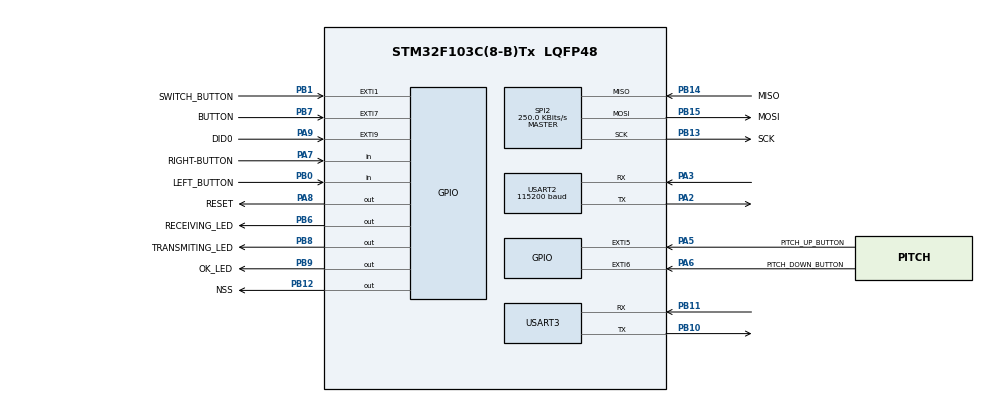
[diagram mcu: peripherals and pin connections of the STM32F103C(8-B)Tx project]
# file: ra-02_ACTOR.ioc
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Dma.Request0=USART2_TX
Dma.Request1=USART3_TX
Dma.Request2=USART3_RX
Dma.USART2_TX.0.Direction=DMA_MEMORY_TO_PERIPH
Dma.USART2_TX.0.Instance=DMA1_Channel7
Dma.USART2_TX.0.MemDataAlignment=DMA_MDATAALIGN_BYTE
Dma.USART2_TX.0.MemInc=DMA_MINC_ENABLE
Dma.USART2_TX.0.Mode=DMA_NORMAL
Dma.USART2_TX.0.PeriphDataAlignment=DMA_PDATAALIGN_BYTE
Dma.USART2_TX.0.PeriphInc=DMA_PINC_DISABLE
Dma.USART2_TX.0.Priority=DMA_PRIORITY_VERY_HIGH
Dma.USART3_RX.2.Direction=DMA_PERIPH_TO_MEMORY
Dma.USART3_RX.2.Instance=DMA1_Channel3
Dma.USART3_RX.2.MemDataAlignment=DMA_MDATAALIGN_BYTE
Dma.USART3_RX.2.MemInc=DMA_MINC_ENABLE
Dma.USART3_RX.2.Mode=DMA_NORMAL
Dma.USART3_RX.2.PeriphDataAlignment=DMA_PDATAALIGN_BYTE
Dma.USART3_RX.2.PeriphInc=DMA_PINC_DISABLE
Dma.USART3_RX.2.Priority=DMA_PRIORITY_LOW
Dma.USART3_TX.1.Direction=DMA_MEMORY_TO_PERIPH
Dma.USART3_TX.1.Instance=DMA1_Channel2
Dma.USART3_TX.1.MemDataAlignment=DMA_MDATAALIGN_BYTE
Dma.USART3_TX.1.MemInc=DMA_MINC_ENABLE
Dma.USART3_TX.1.Mode=DMA_NORMAL
Dma.USART3_TX.1.PeriphDataAlignment=DMA_PDATAALIGN_BYTE
Dma.USART3_TX.1.PeriphInc=DMA_PINC_DISABLE
Dma.USART3_TX.1.Priority=DMA_PRIORITY_LOW
FREERTOS.Tasks01=defaultTask,24,128,StartDefaultTask,Default,NULL,Dynamic,NULL,NULL
FREERTOS.configENABLE_FPU=1
FREERTOS.configTOTAL_HEAP_SIZE=1024
FREERTOS.configUSE_NEWLIB_REENTRANT=1
Mcu.Family=STM32F1
Mcu.Name=STM32F103C(8-B)Tx
Mcu.Package=LQFP48
NVIC.DMA1_Channel2_IRQn=true\:5\:0\:false\:false\:true\:true\:false\:true\:true
NVIC.DMA1_Channel3_IRQn=true\:5\:0\:false\:false\:true\:true\:false\:true\:true
NVIC.DMA1_Channel7_IRQn=true\:5\:0\:false\:false\:true\:true\:false\:true\:true
NVIC.EXTI1_IRQn=true\:5\:0\:false\:false\:true\:true\:true\:true\:true
NVIC.EXTI9_5_IRQn=true\:5\:0\:false\:false\:true\:true\:true\:true\:true
NVIC.PriorityGroup=NVIC_PRIORITYGROUP_4
NVIC.TIM3_IRQn=true\:15\:0\:false\:false\:true\:false\:false\:true\:true
NVIC.TimeBase=TIM3_IRQn
NVIC.TimeBaseIP=TIM3
NVIC.USART2_IRQn=true\:5\:0\:false\:false\:true\:true\:true\:true\:true
NVIC.USART3_IRQn=true\:5\:0\:false\:false\:true\:true\:true\:true\:true
PA13.Mode=Serial_Wire
PA13.Signal=SYS_JTMS-SWDIO
PA14.Mode=Serial_Wire
PA14.Signal=SYS_JTCK-SWCLK
PA2.Mode=Asynchronous
PA2.Signal=USART2_TX
PA3.Mode=Asynchronous
PA3.Signal=USART2_RX
PA5.GPIO_Label=PITCH_UP_BUTTON
PA5.GPIO_PuPd=GPIO_PULLDOWN
PA5.Signal=GPXTI5
PA6.GPIO_Label=PITCH_DOWN_BUTTON
PA6.GPIO_PuPd=GPIO_PULLDOWN
PA6.Signal=GPXTI6
PA7.GPIO_Label=RIGHT-BUTTON
PA7.Signal=GPIO_Input
PA8.GPIO_Label=RESET
PA8.PinState=GPIO_PIN_SET
PA8.Signal=GPIO_Output
PA9.GPIO_Label=DID0
PA9.Signal=GPXTI9
PB0.GPIO_Label=LEFT_BUTTON
PB0.Signal=GPIO_Input
PB1.GPIO_Label=SWITCH_BUTTON
PB1.GPIO_PuPd=GPIO_PULLDOWN
PB1.Signal=GPXTI1
PB10.Mode=Asynchronous
PB10.Signal=USART3_TX
PB11.Mode=Asynchronous
PB11.Signal=USART3_RX
PB12.GPIO_Label=NSS
PB12.PinState=GPIO_PIN_SET
PB12.Signal=GPIO_Output
PB13.GPIO_Label=SCK
PB13.Mode=Full_Duplex_Master
PB13.Signal=SPI2_SCK
PB14.GPIO_Label=MISO
PB14.Mode=Full_Duplex_Master
PB14.Signal=SPI2_MISO
PB15.GPIO_Label=MOSI
PB15.Mode=Full_Duplex_Master
PB15.Signal=SPI2_MOSI
PB6.GPIO_Label=RECEIVING_LED
PB6.Signal=GPIO_Output
PB7.GPIO_Label=BUTTON
PB7.GPIO_ModeDefaultEXTI=GPIO_MODE_IT_RISING
PB7.GPIO_PuPd=GPIO_PULLDOWN
PB7.Signal=GPXTI7
PB8.GPIO_Label=TRANSMITING_LED
PB8.Signal=GPIO_Output
PB9.GPIO_Label=OK_LED
PB9.Signal=GPIO_Output
PD0-OSC_IN.Mode=HSE-External-Oscillator
PD0-OSC_IN.Signal=RCC_OSC_IN
PD1-OSC_OUT.Mode=HSE-External-Oscillator
PD1-OSC_OUT.Signal=RCC_OSC_OUT
ProjectManager.HeapSize=0x200
ProjectManager.StackSize=0x400
ProjectManager.TargetToolchain=STM32CubeIDE
RCC.APB1Freq_Value=8000000
RCC.APB2Freq_Value=8000000
SPI2.BaudRatePrescaler=SPI_BAUDRATEPRESCALER_32
SPI2.CalculateBaudRate=250.0 KBits/s
SPI2.Direction=SPI_DIRECTION_2LINES
SPI2.Mode=SPI_MODE_MASTER
SPI2.VirtualType=VM_MASTER
USART2.BaudRate=115200
USART2.VirtualMode=VM_ASYNC
USART3.VirtualMode=VM_ASYNC
VP_FREERTOS_VS_CMSIS_V2.Mode=CMSIS_V2
VP_SYS_VS_tim3.Mode=TIM3
board=custom

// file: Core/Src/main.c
/* USER CODE BEGIN Header */
/**
  ******************************************************************************
  * @file           : main.c
  * @brief          : Main program body
  ******************************************************************************
  * @attention
  *
  * Copyright (c) 2026 STMicroelectronics.
  * All rights reserved.
  *
  * This software is licensed under terms that can be found in the LICENSE file
  * in the root directory of this software component.
  * If no LICENSE file comes with this software, it is provided AS-IS.
  *
  ******************************************************************************
  */
/* USER CODE END Header */
#include "main.h"
#include "cmsis_os.h"
#include "dma.h"
#include "spi.h"
#include "usart.h"
#include "gpio.h"
#include "LoRa/LoRa_Startup.h"

void SystemClock_Config(void);
void MX_FREERTOS_Init(void);

int main(void)
{

  /* MCU Configuration--------------------------------------------------------*/

  /* Reset of all peripherals, Initializes the Flash interface and the Systick. */
  HAL_Init();

  /* Configure the system clock */
  SystemClock_Config();

  /* Initialize all configured peripherals */
  MX_GPIO_Init();
  MX_DMA_Init();
  MX_SPI2_Init();
  MX_USART2_UART_Init();
  MX_USART3_UART_Init();
  /* USER CODE BEGIN 2 */
  LoRa_Startup();

  /* USER CODE END 2 */

  /* Init scheduler */
  osKernelInitialize();  /* Call init function for freertos objects (in cmsis_os2.c) */
  MX_FREERTOS_Init();

  /* Start scheduler */
  osKernelStart();

  /* We should never get here as control is now taken by the scheduler */

  /* Infinite loop */
  while (1)
  {

  }
}

void SystemClock_Config(void)
{
  RCC_OscInitTypeDef RCC_OscInitStruct = {0};
  RCC_ClkInitTypeDef RCC_ClkInitStruct = {0};

  /** Initializes the RCC Oscillators according to the specified parameters
  * in the RCC_OscInitTypeDef structure.
  */
  RCC_OscInitStruct.OscillatorType = RCC_OSCILLATORTYPE_HSI;
  RCC_OscInitStruct.HSIState = RCC_HSI_ON;
  RCC_OscInitStruct.HSICalibrationValue = RCC_HSICALIBRATION_DEFAULT;
  RCC_OscInitStruct.PLL.PLLState = RCC_PLL_NONE;
  if (HAL_RCC_OscConfig(&RCC_OscInitStruct) != HAL_OK)
  {
    Error_Handler();
  }

  /** Initializes the CPU, AHB and APB buses clocks
  */
  RCC_ClkInitStruct.ClockType = RCC_CLOCKTYPE_HCLK|RCC_CLOCKTYPE_SYSCLK
                              |RCC_CLOCKTYPE_PCLK1|RCC_CLOCKTYPE_PCLK2;
  RCC_ClkInitStruct.SYSCLKSource = RCC_SYSCLKSOURCE_HSI;
  RCC_ClkInitStruct.AHBCLKDivider = RCC_SYSCLK_DIV1;
  RCC_ClkInitStruct.APB1CLKDivider = RCC_HCLK_DIV1;
  RCC_ClkInitStruct.APB2CLKDivider = RCC_HCLK_DIV1;

  if (HAL_RCC_ClockConfig(&RCC_ClkInitStruct, FLASH_LATENCY_0) != HAL_OK)
  {
    Error_Handler();
  }
}

void HAL_TIM_PeriodElapsedCallback(TIM_HandleTypeDef *htim)
{
  if (htim->Instance == TIM3)
  {
    HAL_IncTick();
  }
}

void Error_Handler(void)
{
  __disable_irq();
  while (1)
  {
  }
}
